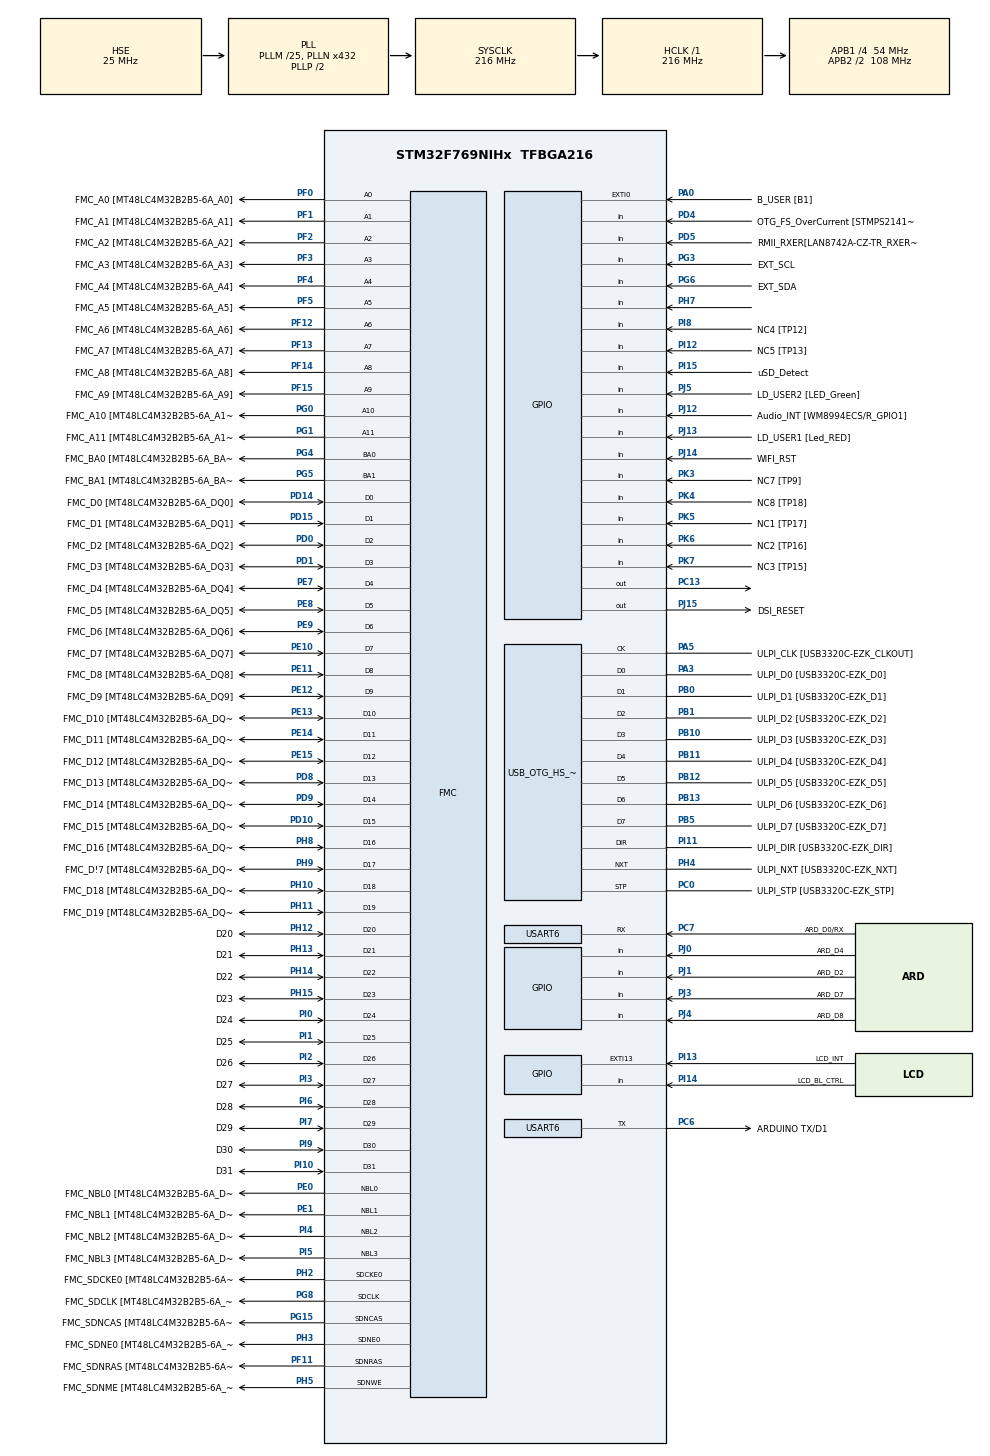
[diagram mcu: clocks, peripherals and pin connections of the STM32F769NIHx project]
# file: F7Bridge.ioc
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DSIHOST_CKN.GPIO_Label=DSI_CK_N
DSIHOST_CKN.Signal=DSIHOST_CKN
DSIHOST_CKP.GPIO_Label=DSI_CK_P
DSIHOST_CKP.Signal=DSIHOST_CKP
DSIHOST_D0N.GPIO_Label=DSI_D0_N
DSIHOST_D0N.Signal=DSIHOST_D0N
DSIHOST_D0P.GPIO_Label=DSI_D0_p
DSIHOST_D0P.Signal=DSIHOST_D0P
DSIHOST_D1N.GPIO_Label=DSI_D1_N
DSIHOST_D1N.Signal=DSIHOST_D1N
DSIHOST_D1P.GPIO_Label=DSI_D1_P
DSIHOST_D1P.Signal=DSIHOST_D1P
FATFS._FS_RPATH=2
FATFS._USE_LFN=3
FATFS._USE_MUTEX=1
FATFS._USE_STRFUNC=0
FATFS._VOLUMES=2
FMC.CASLatency1=FMC_SDRAM_CAS_LATENCY_3
FMC.ExitSelfRefreshDelay1=7
FMC.LoadToActiveDelay1=2
FMC.RCDDelay1=2
FMC.RPDelay1=2
FMC.RPDelay2=2
FMC.ReadBurst1=FMC_SDRAM_RBURST_ENABLE
FMC.ReadBurst2=FMC_SDRAM_RBURST_ENABLE
FMC.RowCycleDelay1=7
FMC.RowCycleDelay2=7
FMC.SDClockPeriod1=FMC_SDRAM_CLOCK_PERIOD_2
FMC.SDClockPeriod2=FMC_SDRAM_CLOCK_PERIOD_2
FMC.SelfRefreshTime1=4
FMC.WriteRecoveryTime1=3
FREERTOS.Tasks01=defaultTask,0,4096,StartDefaultTask,Default,NULL,Static,defaultTaskBuffer,defaultTaskControlBlock
FREERTOS.configCHECK_FOR_STACK_OVERFLOW=2
FREERTOS.configMINIMAL_STACK_SIZE=256
FREERTOS.configTOTAL_HEAP_SIZE=65536
FREERTOS.configUSE_APPLICATION_TASK_TAG=1
FREERTOS.configUSE_COUNTING_SEMAPHORES=1
FREERTOS.configUSE_IDLE_HOOK=1
FREERTOS.configUSE_MALLOC_FAILED_HOOK=1
FREERTOS.configUSE_RECURSIVE_MUTEXES=1
Mcu.Family=STM32F7
Mcu.Name=STM32F769NIHx
Mcu.Package=TFBGA216
NVIC.OTG_HS_IRQn=true\:5\:0\:false\:false\:true\:true\:true\:true
NVIC.PriorityGroup=NVIC_PRIORITYGROUP_4
NVIC.TIM6_DAC_IRQn=true\:0\:0\:false\:false\:true\:false\:false\:true
NVIC.TimeBase=TIM6_DAC_IRQn
NVIC.TimeBaseIP=TIM6
NVIC.USART6_IRQn=true\:0\:0\:false\:false\:true\:false\:true\:true
PA0/WKUP.GPIO_Label=B_USER [B1]
PA0/WKUP.Signal=GPXTI0
PA1.GPIO_Label=RMII_REF_CLK [LAN8742A-CZ-TR_REFCLK0]
PA1.Signal=ETH_REF_CLK
PA10.GPIO_Label=VCP_RX 
PA10.Signal=USART1_RX
PA11.GPIO_Label=SPI2_NSS
PA11.Signal=SPI2_NSS
PA12.GPIO_Label=ARD_D13/SCK
PA12.GPIO_Mode=GPIO_MODE_AF_PP
PA12.GPIO_PuPd=GPIO_NOPULL
PA12.GPIO_Speed=GPIO_SPEED_FREQ_LOW
PA12.Signal=SPI2_SCK
PA13.GPIO_Label=SWDIO
PA13.Mode=Trace_Asynchronous_SW
PA13.Signal=SYS_JTMS-SWDIO
PA14.GPIO_Label=SWCLK
PA14.Mode=Trace_Asynchronous_SW
PA14.Signal=SYS_JTCK-SWCLK
PA15.GPIO_Label=CEC
PA15.Signal=CEC
PA2.GPIO_Label=RMII_MDIO [LAN8742A-CZ-TR_MDIO]
PA2.Signal=ETH_MDIO
PA3.GPIO_Label=ULPI_D0 [USB3320C-EZK_D0]
PA3.Mode=Host_HS
PA3.Signal=USB_OTG_HS_ULPI_D0
PA5.GPIO_Label=ULPI_CLK [USB3320C-EZK_CLKOUT]
PA5.Mode=Host_HS
PA5.Signal=USB_OTG_HS_ULPI_CK
PA6.GPIO_Label=ARD_A0
PA6.Signal=ADCx_IN6
PA7.GPIO_Label=RMII_CRS_DV [LAN8742A-CZ-TR_CRS_DV]
PA7.Signal=ETH_CRS_DV
PA8.GPIO_Label=CEC_CLK [TP2]
PA8.Signal=RCC_MCO_1
PA9.GPIO_Label=VCP_TX [STM32F103CBT6_PA3]
PA9.GPIO_Mode=GPIO_MODE_AF_PP
PA9.GPIO_PuPd=GPIO_NOPULL
PA9.GPIO_Speed=GPIO_SPEED_FREQ_LOW
PA9.Signal=USART1_TX
PB0.GPIO_Label=ULPI_D1 [USB3320C-EZK_D1]
PB0.Mode=Host_HS
PB0.Signal=USB_OTG_HS_ULPI_D1
PB1.GPIO_Label=ULPI_D2 [USB3320C-EZK_D2]
PB1.Mode=Host_HS
PB1.Signal=USB_OTG_HS_ULPI_D2
PB10.GPIO_Label=ULPI_D3 [USB3320C-EZK_D3]
PB10.Mode=Host_HS
PB10.Signal=USB_OTG_HS_ULPI_D3
PB11.GPIO_Label=ULPI_D4 [USB3320C-EZK_D4]
PB11.Mode=Host_HS
PB11.Signal=USB_OTG_HS_ULPI_D4
PB12.GPIO_Label=ULPI_D5 [USB3320C-EZK_D5]
PB12.Mode=Host_HS
PB12.Signal=USB_OTG_HS_ULPI_D5
PB13.GPIO_Label=ULPI_D6 [USB3320C-EZK_D6]
PB13.Mode=Host_HS
PB13.Signal=USB_OTG_HS_ULPI_D6
PB14.GPIO_Label=ARDUINO MISO/D12
PB14.GPIO_Mode=GPIO_MODE_AF_PP
PB14.GPIO_PuPd=GPIO_NOPULL
PB14.GPIO_Speed=GPIO_SPEED_FREQ_LOW
PB14.Signal=SPI2_MISO
PB15.GPIO_Label=ARDUINO MOSI/PWM/D11
PB15.GPIO_Mode=GPIO_MODE_AF_PP
PB15.GPIO_PuPd=GPIO_NOPULL
PB15.GPIO_Speed=GPIO_SPEED_FREQ_LOW
PB15.Signal=SPI2_MOSI
PB2.Signal=QUADSPI_CLK
PB3.Mode=Trace_Asynchronous_SW
PB3.Signal=SYS_JTDO-SWO
PB4.GPIO_Label=uSD_D3
PB4.Signal=SDMMC2_D3
PB5.GPIO_Label=ULPI_D7 [USB3320C-EZK_D7]
PB5.Mode=Host_HS
PB5.Signal=USB_OTG_HS_ULPI_D7
PB6.GPIO_Label=QSPI_NCS [N25Q128A13EF840E_S]
PB6.Signal=QUADSPI_BK1_NCS
PB7.GPIO_Label=AUDIO_SDA [WM8994ECS/R_SDA]
PB7.Signal=I2C4_SDA
PB8.GPIO_Label=ARDUINO SCL/D15
PB8.GPIO_Mode=GPIO_MODE_AF_OD
PB8.GPIO_PuPd=GPIO_NOPULL
PB8.GPIO_Speed=GPIO_SPEED_FREQ_LOW
PB8.Signal=I2C1_SCL
PB9.GPIO_Label=ARDUINO SDA/D14
PB9.GPIO_Mode=GPIO_MODE_AF_OD
PB9.GPIO_PuPd=GPIO_NOPULL
PB9.GPIO_Speed=GPIO_SPEED_FREQ_LOW
PB9.Signal=I2C1_SDA
PC0.GPIO_Label=ULPI_STP [USB3320C-EZK_STP]
PC0.Mode=Host_HS
PC0.Signal=USB_OTG_HS_ULPI_STP
PC1.GPIO_Label=RMII_MDC [LAN8742A-CZ-TR_MDC]
PC1.Signal=ETH_MDC
PC10.GPIO_Label=QSPI_D1 [MT25QL512ABB1EW9_DQ1]
PC10.Signal=QUADSPI_BK1_IO1
PC11.GPIO_Label=DFSDM_DATIN5 [TP5]
PC11.Signal=S_DATAIN5DFSDM1
PC12.GPIO_Label=WIFI_RX
PC12.Signal=UART5_TX
PC13.Signal=GPIO_Output
PC14/OSC32_IN.GPIO_Label=RCC_OSC32_IN
PC14/OSC32_IN.Signal=RCC_OSC32_IN
PC15/OSC32_OUT.GPIO_Label=RCC_OSC32_OUT
PC15/OSC32_OUT.Signal=RCC_OSC32_OUT
PC2.GPIO_Label=ARD_A2
PC2.Signal=ADCx_IN12
PC4.GPIO_Label=RMII_RXD0 [LAN8742A-CZ-TR_RXD0]
PC4.Signal=ETH_RXD0
PC5.GPIO_Label=RMII_RXD1 [LAN8742A-CZ-TR_RXD1]
PC5.Signal=ETH_RXD1
PC6.GPIO_Label=ARDUINO TX/D1
PC6.Mode=Asynchronous
PC6.Signal=USART6_TX
PC7.GPIO_Label=ARD_D0/RX
PC7.Mode=Asynchronous
PC7.Signal=USART6_RX
PC8.GPIO_Label=ARD_D5/PWM
PC8.Signal=S_TIM3_CH3
PC9.GPIO_Label=QSPI_D0 [N25Q128A13EF840E_DQ0]
PC9.Signal=QUADSPI_BK1_IO0
PD0.GPIO_Label=FMC_D2 [MT48LC4M32B2B5-6A_DQ2]
PD0.Signal=FMC_D2_DA2
PD1.GPIO_Label=FMC_D3 [MT48LC4M32B2B5-6A_DQ3]
PD1.Signal=FMC_D3_DA3
PD10.GPIO_Label=FMC_D15 [MT48LC4M32B2B5-6A_DQ15]
PD10.Signal=FMC_D15_DA15
PD11.GPIO_Label=SPDIF_TX [TP20]
PD11.Signal=SAI2_SD_A
PD12.GPIO_Label=AUDIO_SCL [WM8994ECS/R_SCLK]
PD12.Signal=I2C4_SCL
PD13.GPIO_Label=QSPI_D3 [N25Q128A13EF840E_DQ3]
PD13.Signal=QUADSPI_BK1_IO3
PD14.GPIO_Label=FMC_D0 [MT48LC4M32B2B5-6A_DQ0]
PD14.Signal=FMC_D0_DA0
PD15.GPIO_Label=FMC_D1 [MT48LC4M32B2B5-6A_DQ1]
PD15.Signal=FMC_D1_DA1
PD2.GPIO_Label=WIFI_TX
PD2.Signal=UART5_RX
PD3.GPIO_Label=DFSDM_CKOUT [TP102]
PD3.Signal=S_CKOUTDFSDM1
PD4.GPIO_Label=OTG_FS_OverCurrent [STMPS2141STR_Fault]
PD4.Signal=GPIO_Input
PD5.GPIO_Label=RMII_RXER[LAN8742A-CZ-TR_RXERR]
PD5.Signal=GPIO_Input
PD6.GPIO_Label=uSD_CLK
PD6.Signal=SDMMC2_CK
PD7.GPIO_Label=uSD_CMD
PD7.Signal=SDMMC2_CMD
PD8.GPIO_Label=FMC_D13 [MT48LC4M32B2B5-6A_DQ13]
PD8.Signal=FMC_D13_DA13
PD9.GPIO_Label=FMC_D14 [MT48LC4M32B2B5-6A_DQ14]
PD9.Signal=FMC_D14_DA14
PE0.GPIO_Label=FMC_NBL0 [MT48LC4M32B2B5-6A_DQM0]
PE0.Signal=FMC_NBL0
PE1.GPIO_Label=FMC_NBL1 [MT48LC4M32B2B5-6A_DQM1]
PE1.Signal=FMC_NBL1
PE10.GPIO_Label=FMC_D7 [MT48LC4M32B2B5-6A_DQ7]
PE10.Signal=FMC_D7_DA7
PE11.GPIO_Label=FMC_D8 [MT48LC4M32B2B5-6A_DQ8]
PE11.Signal=FMC_D8_DA8
PE12.GPIO_Label=FMC_D9 [MT48LC4M32B2B5-6A_DQ9]
PE12.Signal=FMC_D9_DA9
PE13.GPIO_Label=FMC_D10 [MT48LC4M32B2B5-6A_DQ10]
PE13.Signal=FMC_D10_DA10
PE14.GPIO_Label=FMC_D11 [MT48LC4M32B2B5-6A_DQ11]
PE14.Signal=FMC_D11_DA11
PE15.GPIO_Label=FMC_D12 [MT48LC4M32B2B5-6A_DQ12]
PE15.Signal=FMC_D12_DA12
PE2.GPIO_Label=QSPI_D2 [N25Q128A13EF840E_DQ2]
PE2.Signal=QUADSPI_BK1_IO2
PE3.GPIO_Label=SAI1_SDB [WM8994ECS/R_ADCDAT1]
PE3.Signal=SAI1_SD_B
PE4.GPIO_Label=SAI1_FSA [WM8994ECS/R_LRCLK1]
PE4.Signal=SAI1_FS_A
PE5.GPIO_Label=SAI1_SCKA [WM8994ECS/R_BCLK1]
PE5.Signal=SAI1_SCK_A
PE6.GPIO_Label=SAI1_SDA [WM8994ECS/R_DACDAT1]
PE6.Signal=SAI1_SD_A
PE7.GPIO_Label=FMC_D4 [MT48LC4M32B2B5-6A_DQ4]
PE7.Signal=FMC_D4_DA4
PE8.GPIO_Label=FMC_D5 [MT48LC4M32B2B5-6A_DQ5]
PE8.Signal=FMC_D5_DA5
PE9.GPIO_Label=FMC_D6 [MT48LC4M32B2B5-6A_DQ6]
PE9.Signal=FMC_D6_DA6
PF0.GPIO_Label=FMC_A0 [MT48LC4M32B2B5-6A_A0]
PF0.Signal=FMC_A0
PF1.GPIO_Label=FMC_A1 [MT48LC4M32B2B5-6A_A1]
PF1.Signal=FMC_A1
PF10.GPIO_Label=ARDUINO A1
PF10.GPIO_Mode=GPIO_MODE_ANALOG
PF10.GPIO_PuPd=GPIO_NOPULL
PF10.Signal=ADC3_IN8
PF11.GPIO_Label=FMC_SDNRAS [MT48LC4M32B2B5-6A_RAS]
PF11.Signal=FMC_SDNRAS
PF12.GPIO_Label=FMC_A6 [MT48LC4M32B2B5-6A_A6]
PF12.Signal=FMC_A6
PF13.GPIO_Label=FMC_A7 [MT48LC4M32B2B5-6A_A7]
PF13.Signal=FMC_A7
PF14.GPIO_Label=FMC_A8 [MT48LC4M32B2B5-6A_A8]
PF14.Signal=FMC_A8
PF15.GPIO_Label=FMC_A9 [MT48LC4M32B2B5-6A_A9]
PF15.Signal=FMC_A9
PF2.GPIO_Label=FMC_A2 [MT48LC4M32B2B5-6A_A2]
PF2.Signal=FMC_A2
PF3.GPIO_Label=FMC_A3 [MT48LC4M32B2B5-6A_A3]
PF3.Signal=FMC_A3
PF4.GPIO_Label=FMC_A4 [MT48LC4M32B2B5-6A_A4]
PF4.Signal=FMC_A4
PF5.GPIO_Label=FMC_A5 [MT48LC4M32B2B5-6A_A5]
PF5.Signal=FMC_A5
PF6.GPIO_Label=ARD_D3/PWM
PF6.Signal=S_TIM10_CH1
PF7.GPIO_Label=ARD_D6/PWM
PF7.Signal=S_TIM11_CH1
PF8.GPIO_Label=ARDUINO A3
PF8.GPIO_Mode=GPIO_MODE_ANALOG
PF8.GPIO_PuPd=GPIO_NOPULL
PF8.Signal=ADC3_IN6
PF9.GPIO_Label=ARDUINO A2
PF9.GPIO_Mode=GPIO_MODE_ANALOG
PF9.GPIO_PuPd=GPIO_NOPULL
PF9.Signal=ADC3_IN7
PG0.GPIO_Label=FMC_A10 [MT48LC4M32B2B5-6A_A10]
PG0.Signal=FMC_A10
PG1.GPIO_Label=FMC_A11 [MT48LC4M32B2B5-6A_A11]
PG1.Signal=FMC_A11
PG10.GPIO_Label=uSD_D1
PG10.Signal=SDMMC2_D1
PG11.GPIO_Label=RMII_TX_EN [LAN8742A-CZ-TR_TXEN]
PG11.Signal=ETH_TX_EN
PG12.GPIO_Label=SPDIF_RX [74LVC1G04SE_4]
PG12.Signal=SPDIFRX_IN1
PG13.GPIO_Label=RMII_TXD0 [LAN8742A-CZ-TR_TXD0]
PG13.Signal=ETH_TXD0
PG14.GPIO_Label=RMII_TXD1 [LAN8742A-CZ-TR_TXD1]
PG14.Signal=ETH_TXD1
PG15.GPIO_Label=FMC_SDNCAS [MT48LC4M32B2B5-6A_CAS]
PG15.Signal=FMC_SDNCAS
PG2.GPIO_Label=FMC_A12
PG2.Signal=FMC_A12
PG3.GPIO_Label=EXT_SCL
PG3.Signal=GPIO_Input
PG4.GPIO_Label=FMC_BA0 [MT48LC4M32B2B5-6A_BA0]
PG4.Signal=FMC_A14_BA0
PG5.GPIO_Label=FMC_BA1 [MT48LC4M32B2B5-6A_BA1]
PG5.Signal=FMC_A15_BA1
PG6.GPIO_Label=EXT_SDA
PG6.Signal=GPIO_Input
PG7.GPIO_Label=SAI1_MCLKA [WM8994ECS/R_MCLK1]
PG7.Signal=SAI1_MCLK_A
PG8.GPIO_Label=FMC_SDCLK [MT48LC4M32B2B5-6A_CLK]
PG8.Signal=FMC_SDCLK
PG9.GPIO_Label=uSD_D0
PG9.Signal=SDMMC2_D0
PH0/OSC_IN.GPIO_Label=OSC_25M [NZ2520SB-25.00M_OUT]
PH0/OSC_IN.Mode=HSE-External-Oscillator
PH0/OSC_IN.Signal=RCC_OSC_IN
PH1/OSC_OUT.Mode=HSE-External-Oscillator
PH1/OSC_OUT.Signal=RCC_OSC_OUT
PH10.GPIO_Label=FMC_D18 [MT48LC4M32B2B5-6A_DQ18]
PH10.Signal=FMC_D18
PH11.GPIO_Label=FMC_D19 [MT48LC4M32B2B5-6A_DQ19]
PH11.Signal=FMC_D19
PH12.GPIO_Label=D20
PH12.Signal=FMC_D20
PH13.GPIO_Label=D21
PH13.Signal=FMC_D21
PH14.GPIO_Label=D22
PH14.Signal=FMC_D22
PH15.GPIO_Label=D23
PH15.Signal=FMC_D23
PH2.GPIO_Label=FMC_SDCKE0 [MT48LC4M32B2B5-6A_CKE]
PH2.Mode=SdramChipSelect1_1
PH2.Signal=FMC_SDCKE0
PH3.GPIO_Label=FMC_SDNE0 [MT48LC4M32B2B5-6A_CS]
PH3.Mode=SdramChipSelect1_1
PH3.Signal=FMC_SDNE0
PH4.GPIO_Label=ULPI_NXT [USB3320C-EZK_NXT]
PH4.Mode=Host_HS
PH4.Signal=USB_OTG_HS_ULPI_NXT
PH5.GPIO_Label=FMC_SDNME [MT48LC4M32B2B5-6A_WE]
PH5.Signal=FMC_SDNWE
PH6.GPIO_Label=ARDUINO PWM/D6
PH6.Signal=S_TIM12_CH1
PH7.Signal=GPIO_Input
PH8.GPIO_Label=FMC_D16 [MT48LC4M32B2B5-6A_DQ16]
PH8.Signal=FMC_D16
PH9.GPIO_Label=FMC_D\!7 [MT48LC4M32B2B5-6A_DQ17]
PH9.Signal=FMC_D17
PI0.GPIO_Label=D24
PI0.Signal=FMC_D24
PI1.GPIO_Label=D25
PI1.Signal=FMC_D25
PI10.GPIO_Label=D31
PI10.Signal=FMC_D31
PI11.GPIO_Label=ULPI_DIR [USB3320C-EZK_DIR]
PI11.Mode=Host_HS
PI11.Signal=USB_OTG_HS_ULPI_DIR
PI12.GPIO_Label=NC5 [TP13]
PI12.Signal=GPIO_Input
PI13.GPIO_Label=LCD_INT
PI13.GPIO_ModeDefaultEXTI=GPIO_MODE_EVT_RISING
PI13.Signal=GPXTI13
PI14.GPIO_Label=LCD_BL_CTRL
PI14.Signal=GPIO_Input
PI15.GPIO_Label=uSD_Detect
PI15.Signal=GPIO_Input
PI2.GPIO_Label=D26
PI2.Signal=FMC_D26
PI3.GPIO_Label=D27
PI3.Signal=FMC_D27
PI4.GPIO_Label=FMC_NBL2 [MT48LC4M32B2B5-6A_DQM2]
PI4.Signal=FMC_NBL2
PI5.GPIO_Label=FMC_NBL3 [MT48LC4M32B2B5-6A_DQM3]
PI5.Signal=FMC_NBL3
PI6.GPIO_Label=D28
PI6.Signal=FMC_D28
PI7.GPIO_Label=D29
PI7.Signal=FMC_D29
PI8.GPIO_Label=NC4 [TP12]
PI8.Signal=GPIO_Input
PI9.GPIO_Label=D30
PI9.Signal=FMC_D30
PJ0.GPIO_Label=ARD_D4
PJ0.Signal=GPIO_Input
PJ1.GPIO_Label=ARD_D2
PJ1.Signal=GPIO_Input
PJ12.GPIO_Label=Audio_INT [WM8994ECS/R_GPIO1]
PJ12.Signal=GPIO_Input
PJ13.GPIO_Label=LD_USER1 [Led_RED]
PJ13.Signal=GPIO_Input
PJ14.GPIO_Label=WIFI_RST
PJ14.Signal=GPIO_Input
PJ15.GPIO_Label=DSI_RESET
PJ15.Signal=GPIO_Output
PJ2.GPIO_Label=DSIHOST_TE
PJ2.Signal=DSIHOST_TE
PJ3.GPIO_Label=ARD_D7
PJ3.Signal=GPIO_Input
PJ4.GPIO_Label=ARD_D8
PJ4.Signal=GPIO_Input
PJ5.GPIO_Label=LD_USER2 [LED_Green]
PJ5.Signal=GPIO_Input
PK3.GPIO_Label=NC7 [TP9]
PK3.Signal=GPIO_Input
PK4.GPIO_Label=NC8 [TP18]
PK4.Signal=GPIO_Input
PK5.GPIO_Label=NC1 [TP17]
PK5.Signal=GPIO_Input
PK6.GPIO_Label=NC2 [TP16]
PK6.Signal=GPIO_Input
PK7.GPIO_Label=NC3 [TP15]
PK7.Signal=GPIO_Input
ProjectManager.HeapSize=0x2000
ProjectManager.StackSize=0x4000
ProjectManager.TargetToolchain=MDK-ARM V5.27
RCC.AHBFreq_Value=216000000
RCC.APB1CLKDivider=RCC_HCLK_DIV4
RCC.APB1Freq_Value=54000000
RCC.APB1TimFreq_Value=108000000
RCC.APB2CLKDivider=RCC_HCLK_DIV2
RCC.APB2Freq_Value=108000000
RCC.APB2TimFreq_Value=216000000
RCC.CortexFreq_Value=216000000
RCC.HCLKFreq_Value=216000000
RCC.HSE_VALUE=25000000
RCC.HSI_VALUE=16000000
RCC.LSE_VALUE=32768
RCC.PLL48CLockSelection=RCC_CLK48SOURCE_PLLSAIP
RCC.PLLM=25
RCC.PLLN=432
RCC.PLLQ=4
RCC.PLLSAIP=RCC_PLLSAIP_DIV4
RCC.PLLSAIQ=3
RCC.PLLSourceVirtual=RCC_PLLSOURCE_HSE
RCC.SDMMC2ClockSelection=RCC_SDMMC2CLKSOURCE_CLK48
RCC.SYSCLKFreq_VALUE=216000000
RCC.SYSCLKSource=RCC_SYSCLKSOURCE_PLLCLK
RCC.USBFreq_Value=48000000
RCC.VCOOutputFreq_Value=432000000
SH.ADCx_IN12.0=ADC1_IN12
SH.ADCx_IN6.0=ADC1_IN6
SH.FMC_A0.0=FMC_A0,12b-sda1
SH.FMC_A1.0=FMC_A1,12b-sda1
SH.FMC_A10.0=FMC_A10,12b-sda1
SH.FMC_A11.0=FMC_A11,12b-sda1
SH.FMC_A12.0=FMC_A12
SH.FMC_A14_BA0.0=FMC_BA0,FourSdramBanks1
SH.FMC_A15_BA1.0=FMC_BA1,FourSdramBanks1
SH.FMC_A2.0=FMC_A2,12b-sda1
SH.FMC_A3.0=FMC_A3,12b-sda1
SH.FMC_A4.0=FMC_A4,12b-sda1
SH.FMC_A5.0=FMC_A5,12b-sda1
SH.FMC_A6.0=FMC_A6,12b-sda1
SH.FMC_A7.0=FMC_A7,12b-sda1
SH.FMC_A8.0=FMC_A8,12b-sda1
SH.FMC_A9.0=FMC_A9,12b-sda1
SH.FMC_D0_DA0.0=FMC_D0,sd-32b-d1
SH.FMC_D10_DA10.0=FMC_D10,sd-32b-d1
SH.FMC_D11_DA11.0=FMC_D11,sd-32b-d1
SH.FMC_D12_DA12.0=FMC_D12,sd-32b-d1
SH.FMC_D13_DA13.0=FMC_D13,sd-32b-d1
SH.FMC_D14_DA14.0=FMC_D14,sd-32b-d1
SH.FMC_D15_DA15.0=FMC_D15,sd-32b-d1
SH.FMC_D16.0=FMC_D16,sd-32b-d1
SH.FMC_D17.0=FMC_D17,sd-32b-d1
SH.FMC_D18.0=FMC_D18,sd-32b-d1
SH.FMC_D19.0=FMC_D19,sd-32b-d1
SH.FMC_D1_DA1.0=FMC_D1,sd-32b-d1
SH.FMC_D20.0=FMC_D20,sd-32b-d1
SH.FMC_D21.0=FMC_D21,sd-32b-d1
SH.FMC_D22.0=FMC_D22,sd-32b-d1
SH.FMC_D23.0=FMC_D23,sd-32b-d1
SH.FMC_D24.0=FMC_D24,sd-32b-d1
SH.FMC_D25.0=FMC_D25,sd-32b-d1
SH.FMC_D26.0=FMC_D26,sd-32b-d1
SH.FMC_D27.0=FMC_D27,sd-32b-d1
SH.FMC_D28.0=FMC_D28,sd-32b-d1
SH.FMC_D29.0=FMC_D29,sd-32b-d1
SH.FMC_D2_DA2.0=FMC_D2,sd-32b-d1
SH.FMC_D30.0=FMC_D30,sd-32b-d1
SH.FMC_D31.0=FMC_D31,sd-32b-d1
SH.FMC_D3_DA3.0=FMC_D3,sd-32b-d1
SH.FMC_D4_DA4.0=FMC_D4,sd-32b-d1
SH.FMC_D5_DA5.0=FMC_D5,sd-32b-d1
SH.FMC_D6_DA6.0=FMC_D6,sd-32b-d1
SH.FMC_D7_DA7.0=FMC_D7,sd-32b-d1
SH.FMC_D8_DA8.0=FMC_D8,sd-32b-d1
SH.FMC_D9_DA9.0=FMC_D9,sd-32b-d1
SH.FMC_NBL0.0=FMC_NBL0,Sd4ByteEnable1
SH.FMC_NBL1.0=FMC_NBL1,Sd4ByteEnable1
SH.FMC_NBL2.0=FMC_NBL2,Sd4ByteEnable1
SH.FMC_NBL3.0=FMC_NBL3,Sd4ByteEnable1
SH.FMC_SDCLK.0=FMC_SDCLK,12b-sda1
SH.FMC_SDNCAS.0=FMC_SDNCAS,12b-sda1
SH.FMC_SDNRAS.0=FMC_SDNRAS,12b-sda1
SH.FMC_SDNWE.0=FMC_SDNWE,12b-sda1
SH.S_CKOUTDFSDM1.0=DFSDM1_CKOUT
SH.S_DATAIN5DFSDM1.0=DFSDM1_DATIN5
SH.S_TIM10_CH1.0=TIM10_CH1
SH.S_TIM11_CH1.0=TIM11_CH1
SH.S_TIM12_CH1.0=TIM12_CH1
SH.S_TIM3_CH3.0=TIM3_CH3
USART6.DMADisableonRxErrorParam=ADVFEATURE_DMA_ENABLEONRXERROR
USART6.VirtualMode-Asynchronous=VM_ASYNC
USART6.WordLength=WORDLENGTH_8B
USB_HOST.BSP.number=1
USB_HOST.USBH_DEBUG_LEVEL-MSC_HS=0
USB_HOST.USBH_HandleTypeDef-MSC_HS=hUsbHostHS
USB_HOST.USBH_KEEP_CFG_DESCRIPTOR-MSC_HS=0
USB_HOST.USBH_MAX_NUM_SUPPORTED_CLASS-MSC_HS=1
USB_HOST.USBH_PROCESS_PRIO-MSC_HS=osPriorityNormal
USB_HOST.USBH_PROCESS_STACK_SIZE-MSC_HS=512
USB_HOST.VirtualModeHS=Msc
USB_HOST0.BSP.STBoard=false
USB_HOST0.BSP.api=Unknown
USB_HOST0.BSP.i2caddr=0
USB_HOST0.BSP.instance=PC13
USB_HOST0.BSP.ip=GPIO
USB_HOST0.BSP.mode=Output
USB_HOST0.BSP.name=Drive_VBUS_HS
USB_HOST0.BSP.solution=PC13
USB_OTG_HS.VirtualMode-Host_HS=Host_HS
USB_OTG_HS.dma_enable-Host_HS=DISABLE
USB_OTG_HS.speed-Host_HS=HCD_SPEED_FULL
USB_OTG_HS.use_external_vbus=ENABLE
VP_FATFS_VS_USB.Mode=USB
VP_FREERTOS_VS_CMSIS_V1.Mode=CMSIS_V1
VP_SYS_VS_tim6.Mode=TIM6
VP_USB_HOST_VS_USB_HOST_MSC_HS.Mode=MSC_HS
board=STM32F769I-DISCO

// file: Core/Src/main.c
/* USER CODE BEGIN Header */
/**
  ******************************************************************************
  * @file           : main.c
  * @brief          : Main program body
  ******************************************************************************
  * @attention
  *
  * <h2><center>&copy; Copyright (c) 2021 STMicroelectronics.
  * All rights reserved.</center></h2>
  *
  * This software component is licensed by ST under Ultimate Liberty license
  * SLA0044, the "License"; You may not use this file except in compliance with
  * the License. You may obtain a copy of the License at:
  *                             www.st.com/SLA0044
  *
  ******************************************************************************
  */
/* USER CODE END Header */
#include "main.h"
#include "cmsis_os.h"
#include "fatfs.h"
#include "usart.h"
#include "usb_host.h"
#include "gpio.h"
#include "fmc.h"

/* USER CODE BEGIN Includes */
#include "Board.h"
/* USER CODE END Includes */

void SystemClock_Config(void);
void MX_FREERTOS_Init(void);

int main(void)
{

  /* MCU Configuration--------------------------------------------------------*/

  /* Reset of all peripherals, Initializes the Flash interface and the Systick. */
  HAL_Init();

  /* Configure the system clock */
  SystemClock_Config();

  /* USER CODE BEGIN SysInit */
	///!!!!!!!!!!!!!!!!!!!!!
	///!!!!!!!!!!!!!!!!!!!!!
	///!!!!!!!!!!!!!!!!!!!!!
	///!!!!!!!!!!!!!!!!!!!!!
	//�?е забыть добавить RCC_OscInitStruct.PLL.PLLR = RCC_PLLP_DIV2;
	//Прерывание от USART установить HAL_NVIC_SetPriority(USART6_IRQn, 0, 0);
	///!!!!!!!!!!!!!!!!!!!!!
	///!!!!!!!!!!!!!!!!!!!!!
	///!!!!!!!!!!!!!!!!!!!!!
	///!!!!!!!!!!!!!!!!!!!!!
  /* USER CODE END SysInit */

  /* Initialize all configured peripherals */
  MX_GPIO_Init();
  MX_FMC_Init();
  MX_FATFS_Init();
  MX_USART6_UART_Init();
  /* USER CODE BEGIN 2 */
	/* Return value for USBH from MX_FATFS_Init*/
  if(retUSBH != 0)
  {
		Error_Handler();
	}

//	BSP_LED_Init(LED1);
//	BSP_LED_Init(LED2);
//	for( ;; )
//	{
//		BSP_LED_Toggle(LED1);
//		HAL_Delay(1000);
//		BSP_LED_Toggle(LED1);
//		HAL_Delay(1000);
//	}
	Board_Init();
  /* USER CODE END 2 */

  /* Call init function for freertos objects (in freertos.c) */
  //MX_FREERTOS_Init();
  /* Start scheduler */
  osKernelStart();

  /* We should never get here as control is now taken by the scheduler */
  /* Infinite loop */
  while (1)
  {

  }
}

void SystemClock_Config(void)
{
  RCC_OscInitTypeDef RCC_OscInitStruct = {0};
  RCC_ClkInitTypeDef RCC_ClkInitStruct = {0};
  RCC_PeriphCLKInitTypeDef PeriphClkInitStruct = {0};

  /** Configure the main internal regulator output voltage
  */
  __HAL_RCC_PWR_CLK_ENABLE();
  __HAL_PWR_VOLTAGESCALING_CONFIG(PWR_REGULATOR_VOLTAGE_SCALE1);
  /** Initializes the RCC Oscillators according to the specified parameters
  * in the RCC_OscInitTypeDef structure.
  */
  RCC_OscInitStruct.OscillatorType = RCC_OSCILLATORTYPE_HSE;
  RCC_OscInitStruct.HSEState = RCC_HSE_ON;
  RCC_OscInitStruct.PLL.PLLState = RCC_PLL_ON;
  RCC_OscInitStruct.PLL.PLLSource = RCC_PLLSOURCE_HSE;
  RCC_OscInitStruct.PLL.PLLM = 25;
  RCC_OscInitStruct.PLL.PLLN = 432;
  RCC_OscInitStruct.PLL.PLLP = RCC_PLLP_DIV2;
  RCC_OscInitStruct.PLL.PLLQ = 4;
  if (HAL_RCC_OscConfig(&RCC_OscInitStruct) != HAL_OK)
  {
    Error_Handler();
  }
  /** Activate the Over-Drive mode
  */
  if (HAL_PWREx_EnableOverDrive() != HAL_OK)
  {
    Error_Handler();
  }
  /** Initializes the CPU, AHB and APB buses clocks
  */
  RCC_ClkInitStruct.ClockType = RCC_CLOCKTYPE_HCLK|RCC_CLOCKTYPE_SYSCLK
                              |RCC_CLOCKTYPE_PCLK1|RCC_CLOCKTYPE_PCLK2;
  RCC_ClkInitStruct.SYSCLKSource = RCC_SYSCLKSOURCE_PLLCLK;
  RCC_ClkInitStruct.AHBCLKDivider = RCC_SYSCLK_DIV1;
  RCC_ClkInitStruct.APB1CLKDivider = RCC_HCLK_DIV4;
  RCC_ClkInitStruct.APB2CLKDivider = RCC_HCLK_DIV2;

  if (HAL_RCC_ClockConfig(&RCC_ClkInitStruct, FLASH_LATENCY_7) != HAL_OK)
  {
    Error_Handler();
  }
  PeriphClkInitStruct.PeriphClockSelection = RCC_PERIPHCLK_USART6;
  PeriphClkInitStruct.Usart6ClockSelection = RCC_USART6CLKSOURCE_PCLK2;
  if (HAL_RCCEx_PeriphCLKConfig(&PeriphClkInitStruct) != HAL_OK)
  {
    Error_Handler();
  }
}

 /**
  * @brief  Period elapsed callback in non blocking mode
  * @note   This function is called  when TIM6 interrupt took place, inside
  * HAL_TIM_IRQHandler(). It makes a direct call to HAL_IncTick() to increment
  * a global variable "uwTick" used as application time base.
  * @param  htim : TIM handle
  * @retval None
  */
void HAL_TIM_PeriodElapsedCallback(TIM_HandleTypeDef *htim)
{
  if (htim->Instance == TIM6) {
    HAL_IncTick();
  }
}

void Error_Handler(void)
{
  /* USER CODE BEGIN Error_Handler_Debug */
  /* User can add his own implementation to report the HAL error return state */
	for(;;)
	{
		printf("Error_Handler\n");
		HAL_Delay(1000);
	}
  /* USER CODE END Error_Handler_Debug */
}

#ifdef  USE_FULL_ASSERT
/**
  * @brief  Reports the name of the source file and the source line number
  *         where the assert_param error has occurred.
  * @param  file: pointer to the source file name
  * @param  line: assert_param error line source number
  * @retval None
  */
void assert_failed(uint8_t *file, uint32_t line)
{
  /* USER CODE BEGIN 6 */
  /* User can add his own implementation to report the file name and line number,
     tex: printf("Wrong parameters value: file %s on line %d\r\n", file, line) */
	printf("Wrong parameters value: file %s on line %d\r\n", file, line);
	//Error_Handler();
  /* USER CODE END 6 */
}
#endif /* USE_FULL_ASSERT */

/************************ (C) COPYRIGHT STMicroelectronics *****END OF FILE****/

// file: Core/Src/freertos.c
/* USER CODE BEGIN Header */
/**
  ******************************************************************************
  * File Name          : freertos.c
  * Description        : Code for freertos applications
  ******************************************************************************
  * @attention
  *
  * <h2><center>&copy; Copyright (c) 2021 STMicroelectronics.
  * All rights reserved.</center></h2>
  *
  * This software component is licensed by ST under Ultimate Liberty license
  * SLA0044, the "License"; You may not use this file except in compliance with
  * the License. You may obtain a copy of the License at:
  *                             www.st.com/SLA0044
  *
  ******************************************************************************
  */
/* USER CODE END Header */

#include "FreeRTOS.h"
#include "task.h"
#include "main.h"
#include "cmsis_os.h"

/* USER CODE BEGIN Includes */
#include "usb_host.h"
#include "fatfs.h"
/* USER CODE END Includes */

osThreadId defaultTaskHandle;
uint32_t defaultTaskBuffer[ 4096 ];
osStaticThreadDef_t defaultTaskControlBlock;

void StartDefaultTask(void const * argument);

extern void MX_USB_HOST_Init(void);
void MX_FREERTOS_Init(void); /* (MISRA C 2004 rule 8.1) */

/* GetIdleTaskMemory prototype (linked to static allocation support) */
void vApplicationGetIdleTaskMemory( StaticTask_t **ppxIdleTaskTCBBuffer, StackType_t **ppxIdleTaskStackBuffer, uint32_t *pulIdleTaskStackSize );

/* Hook prototypes */
void vApplicationIdleHook(void);
void vApplicationStackOverflowHook(xTaskHandle xTask, signed char *pcTaskName);
void vApplicationMallocFailedHook(void);

/* USER CODE BEGIN 2 */
__weak void vApplicationIdleHook( void )
{
   /* vApplicationIdleHook() will only be called if configUSE_IDLE_HOOK is set
   to 1 in FreeRTOSConfig.h. It will be called on each iteration of the idle
   task. It is essential that code added to this hook function never attempts
   to block in any way (for example, call xQueueReceive() with a block time
   specified, or call vTaskDelay()). If the application makes use of the
   vTaskDelete() API function (as this demo application does) then it is also
   important that vApplicationIdleHook() is permitted to return to its calling
   function, because it is the responsibility of the idle task to clean up
   memory allocated by the kernel to any task that has since been deleted. */
}
/* USER CODE END 2 */

/* USER CODE BEGIN 4 */
__weak void vApplicationStackOverflowHook(xTaskHandle xTask, signed char *pcTaskName)
{
   /* Run time stack overflow checking is performed if
   configCHECK_FOR_STACK_OVERFLOW is defined to 1 or 2. This hook function is
   called if a stack overflow is detected. */
	printf("FreeRTOS Error!!! ApplicationStackOverflowHook");
	Error_Handler();
}
/* USER CODE END 4 */

/* USER CODE BEGIN 5 */
__weak void vApplicationMallocFailedHook(void)
{
   /* vApplicationMallocFailedHook() will only be called if
   configUSE_MALLOC_FAILED_HOOK is set to 1 in FreeRTOSConfig.h. It is a hook
   function that will get called if a call to pvPortMalloc() fails.
   pvPortMalloc() is called internally by the kernel whenever a task, queue,
   timer or semaphore is created. It is also called by various parts of the
   demo application. If heap_1.c or heap_2.c are used, then the size of the
   heap available to pvPortMalloc() is defined by configTOTAL_HEAP_SIZE in
   FreeRTOSConfig.h, and the xPortGetFreeHeapSize() API function can be used
   to query the size of free heap space that remains (although it does not
   provide information on how the remaining heap might be fragmented). */
	printf("FreeRTOS Error!!! vApplicationMallocFailedHook");
	Error_Handler();
}
/* USER CODE END 5 */

/* USER CODE BEGIN GET_IDLE_TASK_MEMORY */
static StaticTask_t xIdleTaskTCBBuffer;
static StackType_t xIdleStack[configMINIMAL_STACK_SIZE];

void vApplicationGetIdleTaskMemory( StaticTask_t **ppxIdleTaskTCBBuffer, StackType_t **ppxIdleTaskStackBuffer, uint32_t *pulIdleTaskStackSize )
{
  *ppxIdleTaskTCBBuffer = &xIdleTaskTCBBuffer;
  *ppxIdleTaskStackBuffer = &xIdleStack[0];
  *pulIdleTaskStackSize = configMINIMAL_STACK_SIZE;
  /* place for user code */
}
/* USER CODE END GET_IDLE_TASK_MEMORY */

void MX_FREERTOS_Init(void) {

  /* Create the thread(s) */
  /* definition and creation of defaultTask */
  osThreadStaticDef(defaultTask, StartDefaultTask, osPriorityNormal, 0, 4096, defaultTaskBuffer, &defaultTaskControlBlock);
  defaultTaskHandle = osThreadCreate(osThread(defaultTask), NULL);

  /* USER CODE BEGIN RTOS_THREADS */
  /*##-2- Create Application Queue ###########################################*/

  /* USER CODE END RTOS_THREADS */

}

void StartDefaultTask(void const * argument)
{
  /* init code for USB_HOST */
  MX_USB_HOST_Init();
  for(;;)
  {
    osDelay(1);
  }
}

/************************ (C) COPYRIGHT STMicroelectronics *****END OF FILE****/
